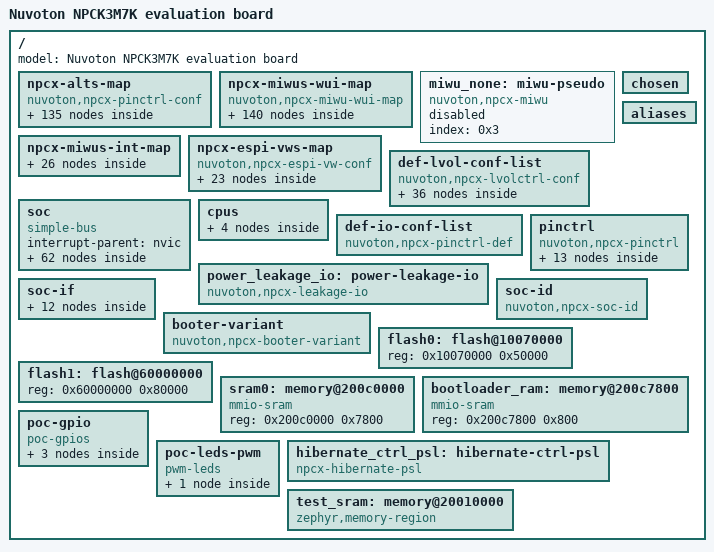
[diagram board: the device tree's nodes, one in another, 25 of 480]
/dts-v1/;

/ {
	#address-cells = < 0x1 >;
	#size-cells = < 0x1 >;
	model = "Nuvoton NPCK3M7K evaluation board";
	npcx-alts-map {
		compatible = "nuvoton,npcx-pinctrl-conf";
		alt0_sp1i_sl: alt00 {
			alts = < &scfg 0x0 0x0 0x0 >;
		};
		alt0_sp1o_sl: alt01 {
			alts = < &scfg 0x0 0x1 0x0 >;
		};
		alt0_ckout_sl: alt02 {
			alts = < &scfg 0x0 0x2 0x0 >;
			phandle = < 0x108 >;
		};
		alt0_spip1_sl: alt03 {
			alts = < &scfg 0x0 0x3 0x0 >;
		};
		alt0_sp2ctl_sl: alt04 {
			alts = < &scfg 0x0 0x4 0x0 >;
		};
		alt0_pvt_spi_sl: alt05 {
			alts = < &scfg 0x0 0x5 0x0 >;
			phandle = < 0xc2 >;
		};
		alt0_shd_bkp_spi_sl: alt05-inv {
			alts = < &scfg 0x0 0x5 0x1 >;
			phandle = < 0xc3 >;
		};
		alt0_shdf_spi_quad: alt06 {
			alts = < &scfg 0x0 0x6 0x0 >;
			phandle = < 0xc4 >;
		};
		alt0_shd1_spi: alt07 {
			alts = < &scfg 0x0 0x7 0x0 >;
			phandle = < 0xc1 >;
		};
		alt1_ovt_sl: alt10 {
			alts = < &scfg 0x1 0x0 0x0 >;
		};
		alt1_urti_sl: alt11 {
			alts = < &scfg 0x1 0x1 0x0 >;
			phandle = < 0xe5 >;
		};
		alt1_urto1_sl: alt12 {
			alts = < &scfg 0x1 0x2 0x0 >;
			phandle = < 0xe6 >;
		};
		alt1_sp1ctl_sl: alt14 {
			alts = < &scfg 0x1 0x4 0x0 >;
		};
		alt1_dpwrok_sl_def: alt15 {
			alts = < &scfg 0x1 0x5 0x0 >;
			phandle = < 0xaf >;
		};
		alt1_vcc_pwrgd_sl_def: alt16 {
			alts = < &scfg 0x1 0x6 0x0 >;
			phandle = < 0xb0 >;
		};
		alt1_lpc_espi_def: alt17 {
			alts = < &scfg 0x1 0x7 0x0 >;
			phandle = < 0xb1 >;
		};
		alt2_lpcpd_sl: alt21 {
			alts = < &scfg 0x2 0x1 0x0 >;
		};
		alt2_clkrun_sl: alt22 {
			alts = < &scfg 0x2 0x2 0x0 >;
		};
		alt2_smi_sl: alt23 {
			alts = < &scfg 0x2 0x3 0x0 >;
		};
		alt2_serirq_sl: alt24 {
			alts = < &scfg 0x2 0x4 0x0 >;
		};
		alt2_ecsci_sl_def: alt25 {
			alts = < &scfg 0x2 0x5 0x0 >;
			phandle = < 0xb2 >;
		};
		alt2_smb1a_sl: alt26 {
			alts = < &scfg 0x2 0x6 0x0 >;
			phandle = < 0xc7 >;
		};
		alt2_smb1b_sl: alt27 {
			alts = < &scfg 0x2 0x7 0x0 >;
			phandle = < 0xc8 >;
		};
		alt3_ta1_1_sl: alt30 {
			alts = < &scfg 0x3 0x0 0x0 >;
			phandle = < 0xe9 >;
		};
		alt3_ta2_1_sl: alt31 {
			alts = < &scfg 0x3 0x1 0x0 >;
			phandle = < 0xed >;
		};
		alt3_tb1_1_sl: alt32 {
			alts = < &scfg 0x3 0x2 0x0 >;
			phandle = < 0xeb >;
		};
		alt3_tb2_1_sl: alt33 {
			alts = < &scfg 0x3 0x3 0x0 >;
			phandle = < 0xef >;
		};
		alt3_ta3_1_sl: alt34 {
			alts = < &scfg 0x3 0x4 0x0 >;
			phandle = < 0xf1 >;
		};
		alt3_tb3_1_sl: alt35 {
			alts = < &scfg 0x3 0x5 0x0 >;
			phandle = < 0xf3 >;
		};
		alt3_tb1_2_sl: alt36 {
			alts = < &scfg 0x3 0x6 0x0 >;
			phandle = < 0xec >;
		};
		alt3_ta1_2_sl: alt37 {
			alts = < &scfg 0x3 0x7 0x0 >;
			phandle = < 0xea >;
		};
		alt4_shd2_spi: alt40 {
			alts = < &scfg 0x4 0x0 0x0 >;
			phandle = < 0xc6 >;
		};
		alt4_noshd2_spi: alt40-inv {
			alts = < &scfg 0x4 0x0 0x1 >;
			phandle = < 0xc5 >;
		};
		alt4_ckout2_sl: alt41 {
			alts = < &scfg 0x4 0x1 0x0 >;
		};
		alt4_clk24m_in2_sl: alt42 {
			alts = < &scfg 0x4 0x2 0x0 >;
		};
		alt4_clk24m_in1_sl: alt43 {
			alts = < &scfg 0x4 0x3 0x0 >;
		};
		alt4_ps2_3_sl: alt44 {
			alts = < &scfg 0x4 0x4 0x0 >;
			phandle = < 0xe8 >;
		};
		alt4_ps2_2_sl: alt46 {
			alts = < &scfg 0x4 0x6 0x0 >;
			phandle = < 0xe7 >;
		};
		alt5_a_pwm_sl: alt50 {
			alts = < &scfg 0x5 0x0 0x0 >;
			phandle = < 0xd1 >;
		};
		alt5_b_pwm_sl: alt51 {
			alts = < &scfg 0x5 0x1 0x0 >;
			phandle = < 0xd2 >;
		};
		alt5_c_pwm_sl: alt52 {
			alts = < &scfg 0x5 0x2 0x0 >;
			phandle = < 0xd3 >;
		};
		alt5_d_pwm_sl: alt53 {
			alts = < &scfg 0x5 0x3 0x0 >;
			phandle = < 0xd4 >;
		};
		alt5_f_pwm_sl: alt55 {
			alts = < &scfg 0x5 0x5 0x0 >;
			phandle = < 0xd5 >;
		};
		alt6_adc0_sl: alt60 {
			alts = < &scfg 0x6 0x0 0x0 >;
			phandle = < 0xd9 >;
		};
		alt6_adc1_sl: alt61 {
			alts = < &scfg 0x6 0x1 0x0 >;
			phandle = < 0xda >;
		};
		alt6_adc2_sl: alt62 {
			alts = < &scfg 0x6 0x2 0x0 >;
			phandle = < 0xdb >;
		};
		alt6_adc3_sl: alt63 {
			alts = < &scfg 0x6 0x3 0x0 >;
			phandle = < 0xdc >;
		};
		alt6_adc4_sl: alt64 {
			alts = < &scfg 0x6 0x4 0x0 >;
			phandle = < 0xdd >;
		};
		alt6_adc5_sl: alt65 {
			alts = < &scfg 0x6 0x5 0x0 >;
			phandle = < 0xde >;
		};
		alt6_adc6_sl: alt66 {
			alts = < &scfg 0x6 0x6 0x0 >;
			phandle = < 0xdf >;
		};
		alt6_adc7_sl: alt67 {
			alts = < &scfg 0x6 0x7 0x0 >;
			phandle = < 0xe0 >;
		};
		alt7_kso12_sl_def: alt72 {
			alts = < &scfg 0x7 0x2 0x0 >;
			phandle = < 0xb3 >;
		};
		alt7_kso13_sl_def: alt73 {
			alts = < &scfg 0x7 0x3 0x0 >;
			phandle = < 0xb4 >;
		};
		alt7_kso14_sl_def: alt74 {
			alts = < &scfg 0x7 0x4 0x0 >;
			phandle = < 0xb5 >;
		};
		alt7_kso15_sl_def: alt75 {
			alts = < &scfg 0x7 0x5 0x0 >;
			phandle = < 0xb6 >;
		};
		alt7_kso16_sl: alt76 {
			alts = < &scfg 0x7 0x6 0x0 >;
			phandle = < 0xf9 >;
		};
		alt7_kso17_sl: alt77 {
			alts = < &scfg 0x7 0x7 0x0 >;
			phandle = < 0xfa >;
		};
		alt8_ga20_sl: alt81 {
			alts = < &scfg 0x8 0x1 0x0 >;
		};
		alt8_kbrst_sl_def: alt82 {
			alts = < &scfg 0x8 0x2 0x0 >;
			phandle = < 0xb7 >;
		};
		alt8_k_pwm_sl: alt85 {
			alts = < &scfg 0x8 0x5 0x0 >;
			phandle = < 0xd8 >;
		};
		alt8_j_pwm_sl: alt86 {
			alts = < &scfg 0x8 0x6 0x0 >;
			phandle = < 0xd7 >;
		};
		alt8_i_pwm_sl: alt87 {
			alts = < &scfg 0x8 0x7 0x0 >;
			phandle = < 0xd6 >;
		};
		alt9_no_ksi0_ksi1_ksi2_ksi3_sl: alt90-inv {
			alts = < &scfg 0x9 0x0 0x1 >;
			phandle = < 0xb8 >;
		};
		alt9_no_ksi4_ksi5_sl: alt92-inv {
			alts = < &scfg 0x9 0x2 0x1 >;
			phandle = < 0xb9 >;
		};
		alt9_no_ksi6_ksi7_sl: alt93-inv {
			alts = < &scfg 0x9 0x3 0x1 >;
			phandle = < 0xba >;
		};
		alt9_no_kso0_kso1_kso2_kso3_sl: alt94-inv {
			alts = < &scfg 0x9 0x4 0x1 >;
			phandle = < 0xbb >;
		};
		alt9_no_kso4_kso5_kso6_kso7_sl: alt95-inv {
			alts = < &scfg 0x9 0x5 0x1 >;
			phandle = < 0xbc >;
		};
		alt9_no_kso8_kso9_sl: alt96-inv {
			alts = < &scfg 0x9 0x6 0x1 >;
			phandle = < 0xbd >;
		};
		alt9_no_kso10_kso11_sl: alt97-inv {
			alts = < &scfg 0x9 0x7 0x1 >;
			phandle = < 0xbe >;
		};
		alta_shi_sl: alta0 {
			alts = < &scfg 0xa 0x0 0x0 >;
		};
		alta_smb6a_sl: alta1 {
			alts = < &scfg 0xa 0x1 0x0 >;
			phandle = < 0xd0 >;
		};
		alta_smb5a_sl: alta2 {
			alts = < &scfg 0xa 0x2 0x0 >;
			phandle = < 0xcf >;
		};
		alta_13c1a_sl: alta4 {
			alts = < &scfg 0xa 0x4 0x0 >;
		};
		alta_13c1b_sl: alta5 {
			alts = < &scfg 0xa 0x5 0x0 >;
		};
		alta_smb3a_sl: alta6 {
			alts = < &scfg 0xa 0x6 0x0 >;
			phandle = < 0xcb >;
		};
		alta_smb4a_sl: alta7 {
			alts = < &scfg 0xa 0x7 0x0 >;
			phandle = < 0xcd >;
		};
		altb_sp2i_sl: altb0 {
			alts = < &scfg 0xb 0x0 0x0 >;
		};
		altb_sp2o_sl: altb1 {
			alts = < &scfg 0xb 0x1 0x0 >;
		};
		altb_ri1_sl: altb2 {
			alts = < &scfg 0xb 0x2 0x0 >;
		};
		altb_cts1_sl: altb3 {
			alts = < &scfg 0xb 0x3 0x0 >;
		};
		altb_rts1_sl: altb4 {
			alts = < &scfg 0xb 0x4 0x0 >;
		};
		altb_ri2_sl: altb5 {
			alts = < &scfg 0xb 0x5 0x0 >;
		};
		altb_cts2_sl: altb6 {
			alts = < &scfg 0xb 0x6 0x0 >;
		};
		altb_rts2_sl: altb7 {
			alts = < &scfg 0xb 0x7 0x0 >;
		};
		altc_smb4b_sl: altc4 {
			alts = < &scfg 0xc 0x4 0x0 >;
			phandle = < 0xce >;
		};
		altc_smb3b_sl: altc5 {
			alts = < &scfg 0xc 0x5 0x0 >;
			phandle = < 0xcc >;
		};
		altc_smb2b_sl: altc6 {
			alts = < &scfg 0xc 0x6 0x0 >;
			phandle = < 0xca >;
		};
		altc_smb2a_sl: altc7 {
			alts = < &scfg 0xc 0x7 0x0 >;
			phandle = < 0xc9 >;
		};
		altd_gpstby0_out_in_sby: altd0 {
			alts = < &scfg 0xd 0x0 0x0 >;
		};
		altd_gpstby1_out_in_sby: altd1 {
			alts = < &scfg 0xd 0x1 0x0 >;
		};
		altd_psl_in0_en_out_def: altd2 {
			alts = < &scfg 0xd 0x2 0x0 >;
		};
		altd_psl_in1_en_out_def: altd3 {
			alts = < &scfg 0xd 0x3 0x0 >;
		};
		altd_psl_in2_en_out_def: altd4 {
			alts = < &scfg 0xd 0x4 0x0 >;
		};
		altd_psl_in3_en_out_def: altd5 {
			alts = < &scfg 0xd 0x5 0x0 >;
		};
		altd_psl_in4_en_out_def: altd6 {
			alts = < &scfg 0xd 0x6 0x0 >;
		};
		altd_psl_in5_en_out_def: altd7 {
			alts = < &scfg 0xd 0x7 0x0 >;
		};
		alte_spip2_sl: alte5 {
			alts = < &scfg 0xe 0x5 0x0 >;
		};
		altf_psl_in0_en_def: altf1 {
			alts = < &scfg 0xf 0x1 0x0 >;
			phandle = < 0xbf >;
		};
		altf_psl_in1_en_def: altf2 {
			alts = < &scfg 0xf 0x2 0x0 >;
			phandle = < 0xc0 >;
		};
		altf_psl_in2_en: altf3 {
			alts = < &scfg 0xf 0x3 0x0 >;
			phandle = < 0xfd >;
		};
		altf_psl_in3_en: altf4 {
			alts = < &scfg 0xf 0x4 0x0 >;
			phandle = < 0xff >;
		};
		altf_psl_in4_en: altf5 {
			alts = < &scfg 0xf 0x5 0x0 >;
			phandle = < 0x101 >;
		};
		altf_psl_in5_en: altf6 {
			alts = < &scfg 0xf 0x6 0x0 >;
			phandle = < 0x103 >;
		};
		altf_psl_out_en_def: altf7 {
			alts = < &scfg 0xf 0x7 0x0 >;
			phandle = < 0x104 >;
		};
		alt10_tb5_sl: alt100 {
			alts = < &scfg 0x10 0x0 0x0 >;
			phandle = < 0xf8 >;
		};
		alt10_ta5_sl: alt101 {
			alts = < &scfg 0x10 0x1 0x0 >;
			phandle = < 0xf7 >;
		};
		alt10_tb4_sl: alt102 {
			alts = < &scfg 0x10 0x2 0x0 >;
			phandle = < 0xf6 >;
		};
		alt10_ta4_sl: alt103 {
			alts = < &scfg 0x10 0x3 0x0 >;
			phandle = < 0xf5 >;
		};
		alt10_tb3_2_sl: alt104 {
			alts = < &scfg 0x10 0x4 0x0 >;
			phandle = < 0xf4 >;
		};
		alt10_ta3_2_sl: alt105 {
			alts = < &scfg 0x10 0x5 0x0 >;
			phandle = < 0xf2 >;
		};
		alt10_tb2_2_sl: alt106 {
			alts = < &scfg 0x10 0x6 0x0 >;
			phandle = < 0xf0 >;
		};
		alt10_ta2_2_sl: alt107 {
			alts = < &scfg 0x10 0x7 0x0 >;
			phandle = < 0xee >;
		};
		alt11_adc8_sl: alt110 {
			alts = < &scfg 0x11 0x0 0x0 >;
			phandle = < 0xe1 >;
		};
		alt11_adc9_sl: alt111 {
			alts = < &scfg 0x11 0x1 0x0 >;
			phandle = < 0xe2 >;
		};
		alt11_adc10_sl: alt112 {
			alts = < &scfg 0x11 0x2 0x0 >;
			phandle = < 0xe3 >;
		};
		alt11_adc11_sl: alt113 {
			alts = < &scfg 0x11 0x3 0x0 >;
			phandle = < 0xe4 >;
		};
		smb1a_pu_sl: alt120 {
			alts = < &scfg 0x12 0x0 0x0 >;
		};
		smb1b_pu_sl: alt121 {
			alts = < &scfg 0x12 0x1 0x0 >;
		};
		smb2a_pu_sl: alt122 {
			alts = < &scfg 0x12 0x2 0x0 >;
		};
		smb2b_pu_sl: alt123 {
			alts = < &scfg 0x12 0x3 0x0 >;
		};
		smb3a_pu_sl: alt124 {
			alts = < &scfg 0x12 0x4 0x0 >;
		};
		smb3b_pu_sl: alt125 {
			alts = < &scfg 0x12 0x5 0x0 >;
		};
		smb4a_pu_sl: alt126 {
			alts = < &scfg 0x12 0x6 0x0 >;
		};
		smb4b_pu_sl: alt127 {
			alts = < &scfg 0x12 0x7 0x0 >;
		};
		altcx_psl_in0_ahi: alt131 {
			alts = < &scfg 0x13 0x1 0x0 >;
			phandle = < 0xfb >;
		};
		altcx_psl_in1_ahi: alt132 {
			alts = < &scfg 0x13 0x2 0x0 >;
			phandle = < 0xfc >;
		};
		altcx_psl_in2_ahi: alt133 {
			alts = < &scfg 0x13 0x3 0x0 >;
			phandle = < 0xfe >;
		};
		altcx_psl_in3_ahi: alt134 {
			alts = < &scfg 0x13 0x4 0x0 >;
			phandle = < 0x100 >;
		};
		altcx_psl_in4_ahi: alt135 {
			alts = < &scfg 0x13 0x5 0x0 >;
			phandle = < 0x102 >;
		};
		altcx_psl_in5_ahi: alt136 {
			alts = < &scfg 0x13 0x6 0x0 >;
		};
		altcx_gpio_out_pullen: alt137 {
			alts = < &scfg 0x13 0x7 0x0 >;
		};
		altdx_psl_out_gpo: alt140 {
			alts = < &scfg 0x14 0x0 0x0 >;
			phandle = < 0x107 >;
		};
		altdx_psl_fw_ctl_high: alt141 {
			alts = < &scfg 0x14 0x1 0x0 >;
			phandle = < 0x105 >;
		};
		altdx_psl_fw_ctl_low: alt141-inv {
			alts = < &scfg 0x14 0x1 0x1 >;
			phandle = < 0x106 >;
		};
		altdx_gpstby_rst_bit: alt147 {
			alts = < &scfg 0x14 0x7 0x0 >;
		};
	};
	npcx-miwus-wui-map {
		compatible = "nuvoton,npcx-miwu-wui-map";
		wui_io01: wui0-1-1 {
			miwus = < &miwu0 0x0 0x1 >;
			phandle = < 0x14 >;
		};
		wui_io02: wui0-1-2 {
			miwus = < &miwu0 0x0 0x2 >;
			phandle = < 0x15 >;
		};
		wui_io03: wui0-1-3 {
			miwus = < &miwu0 0x0 0x3 >;
			phandle = < 0x16 >;
		};
		wui_io04: wui0-1-4 {
			miwus = < &miwu0 0x0 0x4 >;
			phandle = < 0x17 >;
		};
		wui_io05: wui0-1-5 {
			miwus = < &miwu0 0x0 0x5 >;
			phandle = < 0x18 >;
		};
		wui_io07: wui0-1-7 {
			miwus = < &miwu0 0x0 0x7 >;
			phandle = < 0x19 >;
		};
		wui_io10: wui0-2-0 {
			miwus = < &miwu0 0x1 0x0 >;
			phandle = < 0x1d >;
		};
		wui_io11: wui0-2-1 {
			miwus = < &miwu0 0x1 0x1 >;
			phandle = < 0x1e >;
		};
		wui_io13: wui0-2-3 {
			miwus = < &miwu0 0x1 0x3 >;
			phandle = < 0x1f >;
		};
		wui_io14: wui0-2-4 {
			miwus = < &miwu0 0x1 0x4 >;
			phandle = < 0x20 >;
		};
		wui_io15: wui0-2-5 {
			miwus = < &miwu0 0x1 0x5 >;
			phandle = < 0x21 >;
		};
		wui_io17: wui0-2-7 {
			miwus = < &miwu0 0x1 0x7 >;
			phandle = < 0x22 >;
		};
		wui_io20: wui0-3-0 {
			miwus = < &miwu0 0x2 0x0 >;
			phandle = < 0x26 >;
		};
		wui_io21: wui0-3-1 {
			miwus = < &miwu0 0x2 0x1 >;
			phandle = < 0x27 >;
		};
		wui_io22: wui0-3-2 {
			miwus = < &miwu0 0x2 0x2 >;
			phandle = < 0x28 >;
		};
		wui_io23: wui0-3-3 {
			miwus = < &miwu0 0x2 0x3 >;
			phandle = < 0x29 >;
		};
		wui_io25: wui0-3-5 {
			miwus = < &miwu0 0x2 0x5 >;
			phandle = < 0x2a >;
		};
		wui_io26: wui0-3-6 {
			miwus = < &miwu0 0x2 0x6 >;
			phandle = < 0x2b >;
		};
		wui_io27: wui0-3-7 {
			miwus = < &miwu0 0x2 0x7 >;
			phandle = < 0x2c >;
		};
		wui_io30: wui0-4-0 {
			miwus = < &miwu0 0x3 0x0 >;
			phandle = < 0x32 >;
		};
		wui_io31: wui0-4-1 {
			miwus = < &miwu0 0x3 0x1 >;
			phandle = < 0x33 >;
		};
		wui_io32: wui0-4-2 {
			miwus = < &miwu0 0x3 0x2 >;
			phandle = < 0x34 >;
		};
		wui_io33: wui0-4-3 {
			miwus = < &miwu0 0x3 0x3 >;
			phandle = < 0x35 >;
		};
		wui_io34: wui0-4-4 {
			miwus = < &miwu0 0x3 0x4 >;
			phandle = < 0x36 >;
		};
		wui_io36: wui0-4-6 {
			miwus = < &miwu0 0x3 0x6 >;
			phandle = < 0x37 >;
		};
		wui_io40: wui0-5-0 {
			miwus = < &miwu0 0x4 0x0 >;
			phandle = < 0x39 >;
		};
		wui_io44: wui0-5-4 {
			miwus = < &miwu0 0x4 0x4 >;
			phandle = < 0x3a >;
		};
		wui_io45: wui0-5-5 {
			miwus = < &miwu0 0x4 0x5 >;
			phandle = < 0x3b >;
		};
		wui_io46: wui0-5-6 {
			miwus = < &miwu0 0x4 0x6 >;
			phandle = < 0x3c >;
		};
		wui_io47: wui0-5-7 {
			miwus = < &miwu0 0x4 0x7 >;
			phandle = < 0x3d >;
		};
		wui_io50: wui0-6-0 {
			miwus = < &miwu0 0x5 0x0 >;
			phandle = < 0x43 >;
		};
		wui_io51: wui0-6-1 {
			miwus = < &miwu0 0x5 0x1 >;
			phandle = < 0x44 >;
		};
		wui_io52: wui0-6-2 {
			miwus = < &miwu0 0x5 0x2 >;
			phandle = < 0x45 >;
		};
		wui_io53: wui0-6-3 {
			miwus = < &miwu0 0x5 0x3 >;
			phandle = < 0x46 >;
		};
		wui_io54: wui0-6-4 {
			miwus = < &miwu0 0x5 0x4 >;
			phandle = < 0x47 >;
		};
		wui_io55: wui0-6-5 {
			miwus = < &miwu0 0x5 0x5 >;
			phandle = < 0x48 >;
		};
		wui_io56: wui0-6-6 {
			miwus = < &miwu0 0x5 0x6 >;
			phandle = < 0x49 >;
		};
		wui_io57: wui0-6-7 {
			miwus = < &miwu0 0x5 0x7 >;
			phandle = < 0x4a >;
		};
		wui_io60: wui0-7-0 {
			miwus = < &miwu0 0x6 0x0 >;
			phandle = < 0x50 >;
		};
		wui_io61: wui0-7-1 {
			miwus = < &miwu0 0x6 0x1 >;
			phandle = < 0x51 >;
		};
		wui_io62: wui0-7-2 {
			miwus = < &miwu0 0x6 0x2 >;
			phandle = < 0x52 >;
		};
		wui_io63: wui0-7-3 {
			miwus = < &miwu0 0x6 0x3 >;
			phandle = < 0x53 >;
		};
		wui_io64: wui0-7-4 {
			miwus = < &miwu0 0x6 0x4 >;
			phandle = < 0x54 >;
		};
		wui_io65: wui0-7-5 {
			miwus = < &miwu0 0x6 0x5 >;
			phandle = < 0x55 >;
		};
		wui_io66: wui0-7-6 {
			miwus = < &miwu0 0x6 0x6 >;
			phandle = < 0x56 >;
		};
		wui_io67: wui0-7-7 {
			miwus = < &miwu0 0x6 0x7 >;
			phandle = < 0x57 >;
		};
		wui_io70: wui0-8-0 {
			miwus = < &miwu0 0x7 0x0 >;
			phandle = < 0x58 >;
		};
		wui_io72: wui0-8-2 {
			miwus = < &miwu0 0x7 0x2 >;
			phandle = < 0x59 >;
		};
		wui_io73: wui0-8-3 {
			miwus = < &miwu0 0x7 0x3 >;
			phandle = < 0x5a >;
		};
		wui_io74: wui0-8-4 {
			miwus = < &miwu0 0x7 0x4 >;
			phandle = < 0x5b >;
		};
		wui_io75: wui0-8-5 {
			miwus = < &miwu0 0x7 0x5 >;
			phandle = < 0x5c >;
		};
		wui_io76: wui0-8-6 {
			miwus = < &miwu0 0x7 0x6 >;
			phandle = < 0x5d >;
		};
		wui_io77: wui0-8-7 {
			miwus = < &miwu0 0x7 0x7 >;
			phandle = < 0x5e >;
		};
		wui_io81: wui1-1-1 {
			miwus = < &miwu1 0x0 0x1 >;
			phandle = < 0x61 >;
		};
		wui_io83: wui1-1-3 {
			miwus = < &miwu1 0x0 0x3 >;
			phandle = < 0x62 >;
		};
		wui_io85: wui1-1-5 {
			miwus = < &miwu1 0x0 0x5 >;
			phandle = < 0x63 >;
		};
		wui_io86: wui1-1-6 {
			miwus = < &miwu1 0x0 0x6 >;
			phandle = < 0x64 >;
		};
		wui_io87: wui1-1-7 {
			miwus = < &miwu1 0x0 0x7 >;
			phandle = < 0x65 >;
		};
		wui_cr_sin1: wui1-1-7-1 {
			miwus = < &miwu1 0x0 0x7 >;
			phandle = < 0xaa >;
		};
		wui_io90: wui1-2-0 {
			miwus = < &miwu1 0x1 0x0 >;
			phandle = < 0x68 >;
		};
		wui_io91: wui1-2-1 {
			miwus = < &miwu1 0x1 0x1 >;
			phandle = < 0x69 >;
		};
		wui_io92: wui1-2-2 {
			miwus = < &miwu1 0x1 0x2 >;
			phandle = < 0x6a >;
		};
		wui_io93: wui1-2-3 {
			miwus = < &miwu1 0x1 0x3 >;
			phandle = < 0x6b >;
		};
		wui_io94: wui1-2-4 {
			miwus = < &miwu1 0x1 0x4 >;
			phandle = < 0x6c >;
		};
		wui_ioa0: wui1-3-0 {
			miwus = < &miwu1 0x2 0x0 >;
			phandle = < 0x6e >;
		};
		wui_ioa1: wui1-3-1 {
			miwus = < &miwu1 0x2 0x1 >;
			phandle = < 0x6f >;
		};
		wui_ioa2: wui1-3-2 {
			miwus = < &miwu1 0x2 0x2 >;
			phandle = < 0x70 >;
		};
		wui_ioa3: wui1-3-3 {
			miwus = < &miwu1 0x2 0x3 >;
			phandle = < 0x71 >;
		};
		wui_ioa4: wui1-3-4 {
			miwus = < &miwu1 0x2 0x4 >;
			phandle = < 0x72 >;
		};
		wui_ioa5: wui1-3-5 {
			miwus = < &miwu1 0x2 0x5 >;
			phandle = < 0x73 >;
		};
		wui_ioa6: wui1-3-6 {
			miwus = < &miwu1 0x2 0x6 >;
			phandle = < 0x74 >;
		};
		wui_ioa7: wui1-3-7 {
			miwus = < &miwu1 0x2 0x7 >;
			phandle = < 0x75 >;
		};
		wui_iob0: wui1-4-0 {
			miwus = < &miwu1 0x3 0x0 >;
			phandle = < 0x76 >;
		};
		wui_shi_cs: wui1-4-3 {
			miwus = < &miwu1 0x3 0x3 >;
		};
		wui_cdbgpwrupreq: wui1-4-4 {
			miwus = < &miwu1 0x3 0x4 >;
		};
		wui_lpc_ev_wkup: wui1-4-5 {
			miwus = < &miwu1 0x3 0x5 >;
		};
		wui_host_acc: wui1-4-6 {
			miwus = < &miwu1 0x3 0x6 >;
			phandle = < 0xa4 >;
		};
		wui_espi_rst: wui1-4-7 {
			miwus = < &miwu1 0x3 0x7 >;
			phandle = < 0xa2 >;
		};
		wui_mswc: wui1-5-2 {
			miwus = < &miwu1 0x4 0x2 >;
		};
		wui_t0out: wui1-5-3 {
			miwus = < &miwu1 0x4 0x3 >;
			phandle = < 0xa1 >;
		};
		wui_iod0: wui1-6-0 {
			miwus = < &miwu1 0x5 0x0 >;
			phandle = < 0x79 >;
		};
		wui_iod3: wui1-6-3 {
			miwus = < &miwu1 0x5 0x3 >;
			phandle = < 0x7a >;
		};
		wui_iod4: wui1-6-4 {
			miwus = < &miwu1 0x5 0x4 >;
			phandle = < 0x7b >;
		};
		wui_iod5: wui1-6-5 {
			miwus = < &miwu1 0x5 0x5 >;
			phandle = < 0x7c >;
		};
		wui_iod6: wui1-6-6 {
			miwus = < &miwu1 0x5 0x6 >;
			phandle = < 0x7d >;
		};
		wui_iod7: wui1-6-7 {
			miwus = < &miwu1 0x5 0x7 >;
			phandle = < 0x7e >;
		};
		wui_ioe0: wui1-7-0 {
			miwus = < &miwu1 0x6 0x0 >;
			phandle = < 0x81 >;
		};
		wui_ioe1: wui1-7-1 {
			miwus = < &miwu1 0x6 0x1 >;
			phandle = < 0x82 >;
		};
		wui_ioe2: wui1-7-2 {
			miwus = < &miwu1 0x6 0x2 >;
			phandle = < 0x83 >;
		};
		wui_ioe3: wui1-7-3 {
			miwus = < &miwu1 0x6 0x3 >;
			phandle = < 0x84 >;
		};
		wui_ioe4: wui1-7-4 {
			miwus = < &miwu1 0x6 0x4 >;
			phandle = < 0x85 >;
		};
		wui_ioe5: wui1-7-5 {
			miwus = < &miwu1 0x6 0x5 >;
			phandle = < 0x86 >;
		};
		wui_ioe6: wui1-7-6 {
			miwus = < &miwu1 0x6 0x6 >;
			phandle = < 0x87 >;
		};
		wui_mtc: wui1-8-0 {
			miwus = < &miwu1 0x7 0x0 >;
		};
		wui_smb1: wui1-8-1 {
			miwus = < &miwu1 0x7 0x1 >;
		};
		wui_smb2: wui1-8-2 {
			miwus = < &miwu1 0x7 0x2 >;
		};
		wui_smb3: wui1-8-3 {
			miwus = < &miwu1 0x7 0x3 >;
		};
		wui_smb4: wui1-8-4 {
			miwus = < &miwu1 0x7 0x4 >;
		};
		wui_smb5: wui1-8-5 {
			miwus = < &miwu1 0x7 0x5 >;
		};
		wui_smb6: wui1-8-6 {
			miwus = < &miwu1 0x7 0x6 >;
		};
		wui_vw_slp_s3: wui2-1-0 {
			miwus = < &miwu2 0x0 0x0 >;
			phandle = < 0x6 >;
		};
		wui_vw_slp_s4: wui2-1-1 {
			miwus = < &miwu2 0x0 0x1 >;
			phandle = < 0x7 >;
		};
		wui_vw_slp_s5: wui2-1-2 {
			miwus = < &miwu2 0x0 0x2 >;
			phandle = < 0x8 >;
		};
		wui_vw_sus_stat: wui2-1-4 {
			miwus = < &miwu2 0x0 0x4 >;
			phandle = < 0x9 >;
		};
		wui_vw_plt_rst: wui2-1-5 {
			miwus = < &miwu2 0x0 0x5 >;
			phandle = < 0xa >;
		};
		wui_vw_oob_rst_warn: wui2-1-6 {
			miwus = < &miwu2 0x0 0x6 >;
			phandle = < 0xb >;
		};
		wui_vw_host_rst_warn: wui2-2-0 {
			miwus = < &miwu2 0x1 0x0 >;
			phandle = < 0xc >;
		};
		wui_vw_sus_warn: wui2-2-4 {
			miwus = < &miwu2 0x1 0x4 >;
			phandle = < 0xd >;
		};
		wui_vw_sus_pwrdn_ack: wui2-2-5 {
			miwus = < &miwu2 0x1 0x5 >;
			phandle = < 0xe >;
		};
		wui_vw_slp_a: wui2-2-7 {
			miwus = < &miwu2 0x1 0x7 >;
			phandle = < 0xf >;
		};
		wui_vw_slp_lan: wui2-3-0 {
			miwus = < &miwu2 0x2 0x0 >;
			phandle = < 0x10 >;
		};
		wui_vw_slp_wlan: wui2-3-1 {
			miwus = < &miwu2 0x2 0x1 >;
			phandle = < 0x11 >;
		};
		wui_vw_pch_to_ec_gen_0: wui2-3-4 {
			miwus = < &miwu2 0x2 0x4 >;
		};
		wui_vw_pch_to_ec_gen_1: wui2-3-5 {
			miwus = < &miwu2 0x2 0x5 >;
		};
		wui_vw_pch_to_ec_gen_2: wui2-3-6 {
			miwus = < &miwu2 0x2 0x6 >;
		};
		wui_vw_pch_to_ec_gen_3: wui2-3-7 {
			miwus = < &miwu2 0x2 0x7 >;
		};
		wui_vw_pch_to_ec_gen_4: wui2-4-0 {
			miwus = < &miwu2 0x3 0x0 >;
		};
		wui_vw_pch_to_ec_gen_5: wui2-4-1 {
			miwus = < &miwu2 0x3 0x1 >;
		};
		wui_vw_pch_to_ec_gen_6: wui2-4-2 {
			miwus = < &miwu2 0x3 0x2 >;
		};
		wui_vw_pch_to_ec_gen_7: wui2-4-3 {
			miwus = < &miwu2 0x3 0x3 >;
		};
		wui_vw_host_c10: wui2-4-4 {
			miwus = < &miwu2 0x3 0x4 >;
		};
		wui_iog5: wui2-5-5 {
			miwus = < &miwu2 0x4 0x5 >;
			phandle = < 0x8d >;
		};
		wui_iog6: wui2-5-6 {
			miwus = < &miwu2 0x4 0x6 >;
			phandle = < 0x8e >;
		};
		wui_iog7: wui2-5-7 {
			miwus = < &miwu2 0x4 0x7 >;
			phandle = < 0x8f >;
		};
		wui_ioh0: wui2-6-0 {
			miwus = < &miwu2 0x5 0x0 >;
			phandle = < 0x90 >;
		};
		wui_ioh1: wui2-6-1 {
			miwus = < &miwu2 0x5 0x1 >;
			phandle = < 0x91 >;
		};
		wui_ioh2: wui2-6-2 {
			miwus = < &miwu2 0x5 0x2 >;
			phandle = < 0x92 >;
		};
		wui_ioh4: wui2-6-4 {
			miwus = < &miwu2 0x5 0x4 >;
			phandle = < 0x93 >;
		};
		wui_io_stb00: wui2-7-0 {
			miwus = < &miwu2 0x6 0x0 >;
			phandle = < 0x94 >;
		};
		wui_io_stb01: wui2-7-1 {
			miwus = < &miwu2 0x6 0x1 >;
			phandle = < 0x95 >;
		};
		wui_io_stb02: wui2-7-2 {
			miwus = < &miwu2 0x6 0x2 >;
			phandle = < 0x96 >;
		};
		wui_io_stb03: wui2-7-3 {
			miwus = < &miwu2 0x6 0x3 >;
			phandle = < 0x97 >;
		};
		wui_io_stb04: wui2-7-4 {
			miwus = < &miwu2 0x6 0x4 >;
			phandle = < 0x98 >;
		};
		wui_io_stb11_psl_in0: wui2-8-1 {
			miwus = < &miwu2 0x7 0x1 >;
			phandle = < 0x99 >;
		};
		wui_io_stb12_psl_in1: wui2-8-2 {
			miwus = < &miwu2 0x7 0x2 >;
			phandle = < 0x9a >;
		};
		wui_io_stb13_psl_in2: wui2-8-3 {
			miwus = < &miwu2 0x7 0x3 >;
			phandle = < 0x9b >;
		};
		wui_io_stb14_psl_in3: wui2-8-4 {
			miwus = < &miwu2 0x7 0x4 >;
			phandle = < 0x9c >;
		};
		wui_io_stb15_psl_in4: wui2-8-5 {
			miwus = < &miwu2 0x7 0x5 >;
			phandle = < 0x9d >;
		};
		wui_io_stb16_psl_in5: wui2-8-6 {
			miwus = < &miwu2 0x7 0x6 >;
			phandle = < 0x9e >;
		};
		wui_none: wui-pseudo {
			miwus = < &miwu_none 0x7 0x7 >;
			phandle = < 0x13 >;
		};
	};
	miwu_none: miwu-pseudo {
		compatible = "nuvoton,npcx-miwu";
		index = < 0x3 >;
		#miwu-cells = < 0x2 >;
		status = "disabled";
		phandle = < 0x5 >;
	};
	npcx-miwus-int-map {
		map_miwu0_groups: map-miwu0-groups {
			compatible = "nuvoton,npcx-miwu-int-map";
			parent = < &miwu0 >;
			group_a0: group-a0-map {
				irq = < 0x28 >;
				irq-prio = < 0x2 >;
				group-mask = < 0x1 >;
			};
			group_b0: group-b0-map {
				irq = < 0x29 >;
				irq-prio = < 0x2 >;
				group-mask = < 0x2 >;
			};
			group_c0: group-c0-map {
				irq = < 0x2a >;
				irq-prio = < 0x2 >;
				group-mask = < 0x4 >;
			};
			group_d0: group-d0-map {
				irq = < 0x2b >;
				irq-prio = < 0x2 >;
				group-mask = < 0x8 >;
			};
			group_e0: group-e0-map {
				irq = < 0x2c >;
				irq-prio = < 0x2 >;
				group-mask = < 0x10 >;
			};
			group_f0: group-f0-map {
				irq = < 0x2d >;
				irq-prio = < 0x2 >;
				group-mask = < 0x20 >;
			};
			group_g0: group-g0-map {
				irq = < 0x2e >;
				irq-prio = < 0x2 >;
				group-mask = < 0x40 >;
			};
			group_h0: group-h0-map {
				irq = < 0x2f >;
				irq-prio = < 0x2 >;
				group-mask = < 0x80 >;
			};
		};
		map_miwu1_groups: map-miwu1-groups {
			compatible = "nuvoton,npcx-miwu-int-map";
			parent = < &miwu1 >;
			group_a1: group-a1-map {
				irq = < 0x30 >;
				irq-prio = < 0x2 >;
				group-mask = < 0x1 >;
			};
			group_b1: group-b1-map {
				irq = < 0x31 >;
				irq-prio = < 0x2 >;
				group-mask = < 0x2 >;
			};
			group_c1: group-c1-map {
				irq = < 0x32 >;
				irq-prio = < 0x2 >;
				group-mask = < 0x4 >;
			};
			group_d1: group-d1-map {
				irq = < 0x33 >;
				irq-prio = < 0x2 >;
				group-mask = < 0x8 >;
			};
			group_e1: group-e1-map {
				irq = < 0xc >;
				irq-prio = < 0x2 >;
				group-mask = < 0x10 >;
			};
			group_f1: group-f1-map {
				irq = < 0x35 >;
				irq-prio = < 0x2 >;
				group-mask = < 0x20 >;
			};
			group_g1: group-g1-map {
				irq = < 0x36 >;
				irq-prio = < 0x2 >;
				group-mask = < 0x40 >;
			};
		};
		map_miwu2_groups: map-miwu2-groups {
			compatible = "nuvoton,npcx-miwu-int-map";
			parent = < &miwu2 >;
			group_a2: group-a2-map {
				irq = < 0x3c >;
				irq-prio = < 0x2 >;
				group-mask = < 0x1 >;
			};
			group_b2: group-b2-map {
				irq = < 0x3d >;
				irq-prio = < 0x2 >;
				group-mask = < 0x2 >;
			};
			group_c2: group-c2-map {
				irq = < 0x3e >;
				irq-prio = < 0x2 >;
				group-mask = < 0x4 >;
			};
			group_d2: group-d2-map {
				irq = < 0x3f >;
				irq-prio = < 0x2 >;
				group-mask = < 0x8 >;
			};
			group_e2: group-e2-map {
				irq = < 0x38 >;
				irq-prio = < 0x2 >;
				group-mask = < 0x10 >;
			};
			group_f2: group-f2-map {
				irq = < 0x39 >;
				irq-prio = < 0x2 >;
				group-mask = < 0x20 >;
			};
			group_g2: group-g2-map {
				irq = < 0x3a >;
				irq-prio = < 0x2 >;
				group-mask = < 0x40 >;
			};
			group_h2: group-h2-map {
				irq = < 0x3b >;
				irq-prio = < 0x2 >;
				group-mask = < 0x80 >;
			};
		};
	};
	npcx-espi-vws-map {
		compatible = "nuvoton,npcx-espi-vw-conf";
		vw-slp-s3 {
			vw-reg = < 0x0 0x1 >;
			vw-wui = < &wui_vw_slp_s3 >;
		};
		vw-slp-s4 {
			vw-reg = < 0x0 0x2 >;
			vw-wui = < &wui_vw_slp_s4 >;
		};
		vw-slp-s5 {
			vw-reg = < 0x0 0x4 >;
			vw-wui = < &wui_vw_slp_s5 >;
		};
		vw-sus-stat {
			vw-reg = < 0x1 0x1 >;
			vw-wui = < &wui_vw_sus_stat >;
		};
		vw-plt-rst {
			vw-reg = < 0x1 0x2 >;
			vw-wui = < &wui_vw_plt_rst >;
		};
		vw-oob-rst-warn {
			vw-reg = < 0x1 0x4 >;
			vw-wui = < &wui_vw_oob_rst_warn >;
		};
		vw-host-rst-warn {
			vw-reg = < 0x2 0x1 >;
			vw-wui = < &wui_vw_host_rst_warn >;
		};
		vw-sus-warn {
			vw-reg = < 0x3 0x1 >;
			vw-wui = < &wui_vw_sus_warn >;
		};
		vw-sus-pwrdn-ack {
			vw-reg = < 0x3 0x2 >;
			vw-wui = < &wui_vw_sus_pwrdn_ack >;
		};
		vw-slp-a {
			vw-reg = < 0x3 0x8 >;
			vw-wui = < &wui_vw_slp_a >;
		};
		vw-slp-lan {
			vw-reg = < 0x4 0x1 >;
			vw-wui = < &wui_vw_slp_lan >;
		};
		vw-slp-wlan {
			vw-reg = < 0x4 0x2 >;
			vw-wui = < &wui_vw_slp_wlan >;
		};
		vw-oob-rst-ack {
			vw-reg = < 0x0 0x1 >;
		};
		vw-wake {
			vw-reg = < 0x0 0x4 >;
		};
		vw-pme {
			vw-reg = < 0x0 0x8 >;
		};
		vw-slv-boot-done {
			vw-reg = < 0x1 0x1 >;
		};
		vw-err-fatal {
			vw-reg = < 0x1 0x2 >;
		};
		vw-err-non-fatal {
			vw-reg = < 0x1 0x4 >;
		};
		vw-slv-boot-sts-with-done {
			vw-reg = < 0x1 0x9 >;
		};
		vw-sci {
			vw-reg = < 0x2 0x1 >;
		};
		vw-smi {
			vw-reg = < 0x2 0x2 >;
		};
		vw-host-rst-ack {
			vw-reg = < 0x2 0x8 >;
		};
		vw-sus-ack {
			vw-reg = < 0x3 0x1 >;
		};
	};
	def-lvol-conf-list {
		compatible = "nuvoton,npcx-lvolctrl-conf";
		lvol_io20: lvol00 {
			lvols = < &scfg 0x0 0x0 >;
			phandle = < 0x2d >;
		};
		lvol_io21: lvol01 {
			lvols = < &scfg 0x0 0x1 >;
			phandle = < 0x2e >;
		};
		lvol_io40: lvol02 {
			lvols = < &scfg 0x0 0x2 >;
			phandle = < 0x3e >;
		};
		lvol_io54: lvol03 {
			lvols = < &scfg 0x0 0x3 >;
			phandle = < 0x4f >;
		};
		lvol_io85: lvol05 {
			lvols = < &scfg 0x0 0x5 >;
			phandle = < 0x66 >;
		};
		lvol_io86: lvol06 {
			lvols = < &scfg 0x0 0x6 >;
			phandle = < 0x67 >;
		};
		lvol_io94: lvol07 {
			lvols = < &scfg 0x0 0x7 >;
			phandle = < 0x6d >;
		};
		lvol_iod5: lvol10 {
			lvols = < &scfg 0x1 0x0 >;
			phandle = < 0x7f >;
		};
		lvol_iod6: lvol11 {
			lvols = < &scfg 0x1 0x1 >;
			phandle = < 0x80 >;
		};
		lvol_io46: lvol12 {
			lvols = < &scfg 0x1 0x2 >;
			phandle = < 0x41 >;
		};
		lvol_io44: lvol13 {
			lvols = < &scfg 0x1 0x3 >;
			phandle = < 0x3f >;
		};
		lvol_io50: lvol14 {
			lvols = < &scfg 0x1 0x4 >;
			phandle = < 0x4b >;
		};
		lvol_io52: lvol15 {
			lvols = < &scfg 0x1 0x5 >;
			phandle = < 0x4d >;
		};
		lvol_ioe1: lvol16 {
			lvols = < &scfg 0x1 0x6 >;
			phandle = < 0x88 >;
		};
		lvol_ioe2: lvol17 {
			lvols = < &scfg 0x1 0x7 >;
			phandle = < 0x89 >;
		};
		lvol_io01: lvol20 {
			lvols = < &scfg 0x2 0x0 >;
			phandle = < 0x1b >;
		};
		lvol_io03: lvol21 {
			lvols = < &scfg 0x2 0x1 >;
			phandle = < 0x1c >;
		};
		lvol_io13: lvol22 {
			lvols = < &scfg 0x2 0x2 >;
			phandle = < 0x23 >;
		};
		lvol_io15: lvol23 {
			lvols = < &scfg 0x2 0x3 >;
			phandle = < 0x24 >;
		};
		lvol_io45: lvol24 {
			lvols = < &scfg 0x2 0x4 >;
			phandle = < 0x40 >;
		};
		lvol_io51: lvol25 {
			lvols = < &scfg 0x2 0x5 >;
			phandle = < 0x4c >;
		};
		lvol_ioe3: lvol26 {
			lvols = < &scfg 0x2 0x6 >;
			phandle = < 0x8a >;
		};
		lvol_ioe4: lvol27 {
			lvols = < &scfg 0x2 0x7 >;
			phandle = < 0x8b >;
		};
		lvol_io22: lvol30 {
			lvols = < &scfg 0x3 0x0 >;
			phandle = < 0x2f >;
		};
		lvol_io17: lvol31 {
			lvols = < &scfg 0x3 0x1 >;
			phandle = < 0x25 >;
		};
		lvol_io74: lvol32 {
			lvols = < &scfg 0x3 0x2 >;
			phandle = < 0x60 >;
		};
		lvol_io73: lvol33 {
			lvols = < &scfg 0x3 0x3 >;
			phandle = < 0x5f >;
		};
		lvol_io31: lvol34 {
			lvols = < &scfg 0x3 0x4 >;
			phandle = < 0x38 >;
		};
		lvol_io23: lvol35 {
			lvols = < &scfg 0x3 0x5 >;
			phandle = < 0x30 >;
		};
		lvol_io53: lvol36 {
			lvols = < &scfg 0x3 0x6 >;
			phandle = < 0x4e >;
		};
		lvol_io47: lvol37 {
			lvols = < &scfg 0x3 0x7 >;
			phandle = < 0x42 >;
		};
		lvol_io25: lvol40 {
			lvols = < &scfg 0x4 0x0 >;
			phandle = < 0x31 >;
		};
		lvol_ioe6: lvol41 {
			lvols = < &scfg 0x4 0x1 >;
			phandle = < 0x8c >;
		};
		lvol_ioc0: lvol42 {
			lvols = < &scfg 0x4 0x2 >;
			phandle = < 0x78 >;
		};
		lvol_iob7: lvol43 {
			lvols = < &scfg 0x4 0x3 >;
			phandle = < 0x77 >;
		};
		lvol_none: lvol-pseudo {
			lvols = < &scfg 0x1f 0x0 >;
			phandle = < 0x1a >;
		};
	};
	chosen {
		zephyr,flash = &flash0;
		zephyr,sram = &sram0;
		zephyr,console = &uart1;
		zephyr,shell-uart = &uart1;
	};
	aliases {
		gpio-out = &gpio_pulse_out;
		gpio-in = &gpio_pulse_in;
		gpio-obs = &gpio_observe_out;
	};
	soc {
		#address-cells = < 0x1 >;
		#size-cells = < 0x1 >;
		compatible = "simple-bus";
		interrupt-parent = < &nvic >;
		ranges;
		nvic: interrupt-controller@e000e100 {
			#address-cells = < 0x1 >;
			compatible = "arm,v7m-nvic";
			reg = < 0xe000e100 0xc00 >;
			interrupt-controller;
			#interrupt-cells = < 0x2 >;
			arm,num-irq-priority-bits = < 0x3 >;
			phandle = < 0x12 >;
		};
		systick: timer@e000e010 {
			compatible = "arm,armv7m-systick";
			reg = < 0xe000e010 0x10 >;
		};
		bbram: bb-ram@400af000 {
			compatible = "nuvoton,npcx-bbram";
			reg = < 0x400af000 0x80 0x400af100 0x1 >;
			reg-names = "memory", "status";
		};
		pcc: clock-controller@4000d000 {
			compatible = "nuvoton,npcx-pcc";
			#clock-cells = < 0x3 >;
			reg = < 0x4000d000 0x2000 0x400b5000 0x2000 >;
			reg-names = "pmc", "cdcg";
			clock-frequency = < 0x55d4a80 >;
			core-prescaler = < 0x6 >;
			apb1-prescaler = < 0x6 >;
			apb2-prescaler = < 0x6 >;
			apb3-prescaler = < 0x6 >;
			ram-pd-depth = < 0xf >;
			pwdwn-ctl-val = < 0xe7 0xfb 0xff 0x7f 0xb7 0xfa 0x7f >;
			phandle = < 0x9f >;
		};
		scfg: scfg@400c3000 {
			compatible = "nuvoton,npcx-scfg";
			reg = < 0x400c3000 0x70 0x400c3070 0x30 0x400a5000 0x2000 >;
			reg-names = "scfg", "dbg", "glue";
			#alt-cells = < 0x3 >;
			#lvol-cells = < 0x2 >;
			phandle = < 0x1 >;
		};
		mdc: mdc@4000c000 {
			compatible = "syscon";
			reg = < 0x4000c000 0xa >;
			reg-io-width = < 0x1 >;
		};
		mdc_header: mdc@4000c00a {
			compatible = "syscon";
			reg = < 0x4000c00a 0x4 >;
			reg-io-width = < 0x2 >;
		};
		miwu0: miwu@400bb000 {
			compatible = "nuvoton,npcx-miwu";
			reg = < 0x400bb000 0x2000 >;
			index = < 0x0 >;
			#miwu-cells = < 0x2 >;
			phandle = < 0x2 >;
		};
		miwu1: miwu@400bd000 {
			compatible = "nuvoton,npcx-miwu";
			reg = < 0x400bd000 0x2000 >;
			index = < 0x1 >;
			#miwu-cells = < 0x2 >;
			phandle = < 0x3 >;
		};
		miwu2: miwu@400bf000 {
			compatible = "nuvoton,npcx-miwu";
			reg = < 0x400bf000 0x2000 >;
			index = < 0x2 >;
			#miwu-cells = < 0x2 >;
			phandle = < 0x4 >;
		};
		gpio0: gpio@40081000 {
			compatible = "nuvoton,npcx-gpio";
			reg = < 0x40081000 0x2000 >;
			gpio-controller;
			index = < 0x0 >;
			#gpio-cells = < 0x2 >;
			wui-maps = < &wui_none &wui_io01 &wui_io02 &wui_io03 &wui_io04 &wui_io05 &wui_none &wui_io07 >;
			lvol-maps = < &lvol_none &lvol_io01 &lvol_none &lvol_io03 &lvol_none &lvol_none &lvol_none &lvol_none >;
		};
		gpio1: gpio@40083000 {
			compatible = "nuvoton,npcx-gpio";
			reg = < 0x40083000 0x2000 >;
			gpio-controller;
			index = < 0x1 >;
			#gpio-cells = < 0x2 >;
			wui-maps = < &wui_io10 &wui_io11 &wui_none &wui_io13 &wui_io14 &wui_io15 &wui_none &wui_io17 >;
			lvol-maps = < &lvol_none &lvol_none &lvol_none &lvol_io13 &lvol_none &lvol_io15 &lvol_none &lvol_io17 >;
		};
		gpio2: gpio@40085000 {
			compatible = "nuvoton,npcx-gpio";
			reg = < 0x40085000 0x2000 >;
			gpio-controller;
			index = < 0x2 >;
			#gpio-cells = < 0x2 >;
			wui-maps = < &wui_io20 &wui_io21 &wui_io22 &wui_io23 &wui_none &wui_io25 &wui_io26 &wui_io27 >;
			lvol-maps = < &lvol_io20 &lvol_io21 &lvol_io22 &lvol_io23 &lvol_none &lvol_io25 &lvol_none &lvol_none >;
		};
		gpio3: gpio@40087000 {
			compatible = "nuvoton,npcx-gpio";
			reg = < 0x40087000 0x2000 >;
			gpio-controller;
			index = < 0x3 >;
			#gpio-cells = < 0x2 >;
			wui-maps = < &wui_io30 &wui_io31 &wui_io32 &wui_io33 &wui_io34 &wui_none &wui_io36 &wui_none >;
			lvol-maps = < &lvol_none &lvol_io31 &lvol_none &lvol_none &lvol_none &lvol_none &lvol_none &lvol_none >;
		};
		gpio4: gpio@40089000 {
			compatible = "nuvoton,npcx-gpio";
			reg = < 0x40089000 0x2000 >;
			gpio-controller;
			index = < 0x4 >;
			#gpio-cells = < 0x2 >;
			wui-maps = < &wui_io40 &wui_none &wui_none &wui_none &wui_io44 &wui_io45 &wui_io46 &wui_io47 >;
			lvol-maps = < &lvol_io40 &lvol_none &lvol_none &lvol_none &lvol_io44 &lvol_io45 &lvol_io46 &lvol_io47 >;
		};
		gpio5: gpio@4008b000 {
			compatible = "nuvoton,npcx-gpio";
			reg = < 0x4008b000 0x2000 >;
			gpio-controller;
			index = < 0x5 >;
			#gpio-cells = < 0x2 >;
			wui-maps = < &wui_io50 &wui_io51 &wui_io52 &wui_io53 &wui_io54 &wui_io55 &wui_io56 &wui_io57 >;
			lvol-maps = < &lvol_io50 &lvol_io51 &lvol_io52 &lvol_io53 &lvol_io54 &lvol_none &lvol_none &lvol_none >;
		};
		gpio6: gpio@4008d000 {
			compatible = "nuvoton,npcx-gpio";
			reg = < 0x4008d000 0x2000 >;
			gpio-controller;
			index = < 0x6 >;
			#gpio-cells = < 0x2 >;
			wui-maps = < &wui_io60 &wui_io61 &wui_io62 &wui_io63 &wui_io64 &wui_io65 &wui_io66 &wui_io67 >;
			lvol-maps = < &lvol_none &lvol_none &lvol_none &lvol_none &lvol_none &lvol_none &lvol_none &lvol_none >;
		};
		gpio7: gpio@4008f000 {
			compatible = "nuvoton,npcx-gpio";
			reg = < 0x4008f000 0x2000 >;
			gpio-controller;
			index = < 0x7 >;
			#gpio-cells = < 0x2 >;
			wui-maps = < &wui_io70 &wui_none &wui_io72 &wui_io73 &wui_io74 &wui_io75 &wui_io76 &wui_io77 >;
			lvol-maps = < &lvol_none &lvol_none &lvol_none &lvol_io73 &lvol_io74 &lvol_none &lvol_none &lvol_none >;
		};
		gpio8: gpio@40091000 {
			compatible = "nuvoton,npcx-gpio";
			reg = < 0x40091000 0x2000 >;
			gpio-controller;
			index = < 0x8 >;
			#gpio-cells = < 0x2 >;
			wui-maps = < &wui_none &wui_io81 &wui_none &wui_io83 &wui_none &wui_io85 &wui_io86 &wui_io87 >;
			lvol-maps = < &lvol_none &lvol_none &lvol_none &lvol_none &lvol_none &lvol_io85 &lvol_io86 &lvol_none >;
		};
		gpio9: gpio@40093000 {
			compatible = "nuvoton,npcx-gpio";
			reg = < 0x40093000 0x2000 >;
			gpio-controller;
			index = < 0x9 >;
			#gpio-cells = < 0x2 >;
			wui-maps = < &wui_io90 &wui_io91 &wui_io92 &wui_io93 &wui_io94 &wui_none &wui_none &wui_none >;
			lvol-maps = < &lvol_none &lvol_none &lvol_none &lvol_none &lvol_io94 &lvol_none &lvol_none &lvol_none >;
		};
		gpioa: gpio@40095000 {
			compatible = "nuvoton,npcx-gpio";
			reg = < 0x40095000 0x2000 >;
			gpio-controller;
			index = < 0xa >;
			#gpio-cells = < 0x2 >;
			wui-maps = < &wui_ioa0 &wui_ioa1 &wui_ioa2 &wui_ioa3 &wui_ioa4 &wui_ioa5 &wui_ioa6 &wui_ioa7 >;
			lvol-maps = < &lvol_none &lvol_none &lvol_none &lvol_none &lvol_none &lvol_none &lvol_none &lvol_none >;
			phandle = < 0x10f >;
		};
		gpiob: gpio@40097000 {
			compatible = "nuvoton,npcx-gpio";
			reg = < 0x40097000 0x2000 >;
			gpio-controller;
			index = < 0xb >;
			#gpio-cells = < 0x2 >;
			wui-maps = < &wui_iob0 &wui_none &wui_none &wui_none &wui_none &wui_none &wui_none &wui_none >;
			lvol-maps = < &lvol_none &lvol_none &lvol_none &lvol_none &lvol_none &lvol_none &lvol_none &lvol_iob7 >;
		};
		gpioc: gpio@40099000 {
			compatible = "nuvoton,npcx-gpio";
			reg = < 0x40099000 0x2000 >;
			gpio-controller;
			index = < 0xc >;
			#gpio-cells = < 0x2 >;
			wui-maps = < &wui_none &wui_none &wui_none &wui_none &wui_none &wui_none &wui_none &wui_none >;
			lvol-maps = < &lvol_ioc0 &lvol_none &lvol_none &lvol_none &lvol_none &lvol_none &lvol_none &lvol_none >;
			phandle = < 0x110 >;
		};
		gpiod: gpio@4009b000 {
			compatible = "nuvoton,npcx-gpio";
			reg = < 0x4009b000 0x2000 >;
			gpio-controller;
			index = < 0xd >;
			#gpio-cells = < 0x2 >;
			wui-maps = < &wui_iod0 &wui_none &wui_none &wui_iod3 &wui_iod4 &wui_iod5 &wui_iod6 &wui_iod7 >;
			lvol-maps = < &lvol_none &lvol_none &lvol_none &lvol_none &lvol_none &lvol_iod5 &lvol_iod6 &lvol_none >;
		};
		gpioe: gpio@4009d000 {
			compatible = "nuvoton,npcx-gpio";
			reg = < 0x4009d000 0x2000 >;
			gpio-controller;
			index = < 0xe >;
			#gpio-cells = < 0x2 >;
			wui-maps = < &wui_ioe0 &wui_ioe1 &wui_ioe2 &wui_ioe3 &wui_ioe4 &wui_ioe5 &wui_ioe6 &wui_none >;
			lvol-maps = < &lvol_none &lvol_ioe1 &lvol_ioe2 &lvol_ioe3 &lvol_ioe4 &lvol_none &lvol_ioe6 &lvol_none >;
		};
		gpiof: gpio@4009f000 {
			compatible = "nuvoton,npcx-gpio";
			reg = < 0x4009f000 0x2000 >;
			gpio-controller;
			index = < 0xf >;
			#gpio-cells = < 0x2 >;
			wui-maps = < &wui_none &wui_none &wui_none &wui_none &wui_none &wui_none &wui_none &wui_none >;
			lvol-maps = < &lvol_none &lvol_none &lvol_none &lvol_none &lvol_none &lvol_none &lvol_none &lvol_none >;
		};
		gpiog: gpio@400a7000 {
			compatible = "nuvoton,npcx-gpio";
			reg = < 0x400a7000 0x2000 >;
			gpio-controller;
			index = < 0x10 >;
			#gpio-cells = < 0x2 >;
			wui-maps = < &wui_none &wui_none &wui_none &wui_none &wui_none &wui_iog5 &wui_iog6 &wui_iog7 >;
			lvol-maps = < &lvol_none &lvol_none &lvol_none &lvol_none &lvol_none &lvol_none &lvol_none &lvol_none >;
		};
		gpioh: gpio@400a9000 {
			compatible = "nuvoton,npcx-gpio";
			reg = < 0x400a9000 0x2000 >;
			gpio-controller;
			index = < 0x11 >;
			#gpio-cells = < 0x2 >;
			wui-maps = < &wui_ioh0 &wui_ioh1 &wui_ioh2 &wui_none &wui_ioh4 &wui_none &wui_none &wui_none >;
			lvol-maps = < &lvol_none &lvol_none &lvol_none &lvol_none &lvol_none &lvol_none &lvol_none &lvol_none >;
		};
		gpiostb0: gpio@400ab000 {
			compatible = "nuvoton,npcx-gpio";
			reg = < 0x400ab000 0x2000 >;
			gpio-controller;
			index = < 0x12 >;
			#gpio-cells = < 0x2 >;
			wui-maps = < &wui_io_stb00 &wui_io_stb01 &wui_io_stb02 &wui_io_stb03 &wui_io_stb04 &wui_none &wui_none &wui_none >;
			lvol-maps = < &lvol_none &lvol_none &lvol_none &lvol_none &lvol_none &lvol_none &lvol_none &lvol_none >;
		};
		gpiostb1: gpio@400ad000 {
			compatible = "nuvoton,npcx-gpio";
			reg = < 0x400ad000 0x2000 >;
			gpio-controller;
			index = < 0x13 >;
			#gpio-cells = < 0x2 >;
			wui-maps = < &wui_none &wui_io_stb11_psl_in0 &wui_io_stb12_psl_in1 &wui_io_stb13_psl_in2 &wui_io_stb14_psl_in3 &wui_io_stb15_psl_in4 &wui_io_stb16_psl_in5 &wui_none >;
			lvol-maps = < &lvol_none &lvol_none &lvol_none &lvol_none &lvol_none &lvol_none &lvol_none &lvol_none >;
		};
		pwma: pwm@40080000 {
			compatible = "nuvoton,npcx-pwm";
			reg = < 0x40080000 0x2000 >;
			pwm-channel = < 0x0 >;
			clocks = < &pcc 0x6 0x2 0x0 >;
			#pwm-cells = < 0x3 >;
			status = "disabled";
		};
		pwmb: pwm@40082000 {
			compatible = "nuvoton,npcx-pwm";
			reg = < 0x40082000 0x2000 >;
			pwm-channel = < 0x1 >;
			clocks = < &pcc 0x6 0x2 0x1 >;
			#pwm-cells = < 0x3 >;
			status = "okay";
			pinctrl-0 = < &pwmb_gp21 >;
			pinctrl-names = "default";
			phandle = < 0x111 >;
		};
		pwmc: pwm@40084000 {
			compatible = "nuvoton,npcx-pwm";
			reg = < 0x40084000 0x2000 >;
			pwm-channel = < 0x2 >;
			clocks = < &pcc 0x6 0x2 0x2 >;
			#pwm-cells = < 0x3 >;
			status = "disabled";
		};
		pwmd: pwm@40086000 {
			compatible = "nuvoton,npcx-pwm";
			reg = < 0x40086000 0x2000 >;
			pwm-channel = < 0x3 >;
			clocks = < &pcc 0x6 0x2 0x3 >;
			#pwm-cells = < 0x3 >;
			status = "disabled";
		};
		pwmf: pwm@4008a000 {
			compatible = "nuvoton,npcx-pwm";
			reg = < 0x4008a000 0x2000 >;
			pwm-channel = < 0x5 >;
			clocks = < &pcc 0x6 0x2 0x5 >;
			#pwm-cells = < 0x3 >;
			status = "disabled";
		};
		pwmi: pwm@40090000 {
			compatible = "nuvoton,npcx-pwm";
			reg = < 0x40090000 0x2000 >;
			pwm-channel = < 0x9 >;
			clocks = < &pcc 0x6 0x0 0x0 >;
			#pwm-cells = < 0x3 >;
			status = "disabled";
		};
		pwmj: pwm@40092000 {
			compatible = "nuvoton,npcx-pwm";
			reg = < 0x40092000 0x2000 >;
			pwm-channel = < 0xa >;
			clocks = < &pcc 0x6 0x0 0x1 >;
			#pwm-cells = < 0x3 >;
			status = "disabled";
		};
		pwmk: pwm@40094000 {
			compatible = "nuvoton,npcx-pwm";
			reg = < 0x40094000 0x2000 >;
			pwm-channel = < 0xb >;
			clocks = < &pcc 0x6 0x0 0x2 >;
			#pwm-cells = < 0x3 >;
			status = "disabled";
		};
		adc0: adc@400d1000 {
			compatible = "nuvoton,npcx-adc";
			#io-channel-cells = < 0x1 >;
			reg = < 0x400d1000 0x2000 >;
			interrupts = < 0x15 0x3 >;
			clocks = < &pcc 0x5 0x4 0x4 >;
			vref-mv = < 0xce4 >;
			status = "disabled";
			channel-count = < 0xc >;
			threshold-count = < 0x6 >;
		};
		twd0: watchdog@400d8000 {
			compatible = "nuvoton,npcx-watchdog";
			reg = < 0x400d8000 0x2000 >;
			t0-out = < &wui_t0out >;
		};
		espi0: espi@4000a000 {
			compatible = "nuvoton,npcx-espi";
			reg = < 0x4000a000 0x2000 >;
			interrupts = < 0xb 0x3 >;
			clocks = < &pcc 0x7 0x6 0x7 >;
			espi-rst-wui = < &wui_espi_rst >;
			rx-plsize = < 0x40 >;
			tx-plsize = < 0x40 >;
			#address-cells = < 0x1 >;
			#size-cells = < 0x0 >;
			#vw-cells = < 0x3 >;
			status = "okay";
			pinctrl-0 = < &espi_lpc_gp10_f7 >;
			pinctrl-names = "default";
		};
		host_sub: lpc@400c1000 {
			compatible = "nuvoton,npcx-host-sub";
			reg = < 0x400c1000 0x2000 0x40010000 0x2000 0x4000e000 0x2000 0x400c7000 0x2000 0x400c9000 0x2000 0x400cb000 0x2000 >;
			reg-names = "mswc", "shm", "c2h", "kbc", "pm_acpi", "pm_hcmd";
			interrupts = < 0x6 0x3 >, < 0x5 0x3 >, < 0x4 0x3 >, < 0x3 0x3 >, < 0xa 0x3 >;
			interrupt-names = "kbc_ibf", "kbc_obe", "pmch_ibf", "pmch_obe", "p80_fifo";
			host-acc-wui = < &wui_host_acc >;
			clocks = < &pcc 0x7 0x5 0x3 >, < &pcc 0x7 0x5 0x4 >, < &pcc 0x7 0x5 0x5 >, < &pcc 0x7 0x5 0x6 >, < &pcc 0x5 0x5 0x7 >;
		};
		i2c_ctrl1: i2c@40003000 {
			compatible = "nuvoton,npcx-i2c-ctrl";
			reg = < 0x40003000 0x1000 >;
			interrupts = < 0x23 0x3 >;
			clocks = < &pcc 0x7 0x3 0x0 >;
			status = "disabled";
			phandle = < 0x109 >;
		};
		i2c_ctrl2: i2c@40004000 {
			compatible = "nuvoton,npcx-i2c-ctrl";
			reg = < 0x40004000 0x1000 >;
			interrupts = < 0x24 0x3 >;
			clocks = < &pcc 0x7 0x3 0x1 >;
			status = "disabled";
			phandle = < 0x10a >;
		};
		i2c_ctrl3: i2c@40005000 {
			compatible = "nuvoton,npcx-i2c-ctrl";
			reg = < 0x40005000 0x1000 >;
			interrupts = < 0x25 0x3 >;
			clocks = < &pcc 0x7 0x3 0x2 >;
			status = "disabled";
			phandle = < 0x10b >;
		};
		i2c_ctrl4: i2c@40006000 {
			compatible = "nuvoton,npcx-i2c-ctrl";
			reg = < 0x40006000 0x1000 >;
			interrupts = < 0x26 0x3 >;
			clocks = < &pcc 0x7 0x3 0x3 >;
			status = "disabled";
			phandle = < 0x10c >;
		};
		i2c_ctrl5: i2c@40007000 {
			compatible = "nuvoton,npcx-i2c-ctrl";
			reg = < 0x40007000 0x1000 >;
			interrupts = < 0x27 0x3 >;
			clocks = < &pcc 0x7 0x3 0x4 >;
			status = "disabled";
			phandle = < 0x10d >;
		};
		i2c_ctrl6: i2c@40008000 {
			compatible = "nuvoton,npcx-i2c-ctrl";
			reg = < 0x40008000 0x1000 >;
			interrupts = < 0x14 0x3 >;
			clocks = < &pcc 0x7 0x3 0x5 >;
			status = "disabled";
			phandle = < 0x10e >;
		};
		tach1: tach@400e1000 {
			compatible = "nuvoton,npcx-tach";
			reg = < 0x400e1000 0x2000 >;
			clocks = < &pcc 0x1 0x1 0x5 >;
			status = "disabled";
		};
		tach2: tach@400e3000 {
			compatible = "nuvoton,npcx-tach";
			reg = < 0x400e3000 0x2000 >;
			clocks = < &pcc 0x1 0x1 0x6 >;
			status = "disabled";
		};
		tach3: tach@400e5000 {
			compatible = "nuvoton,npcx-tach";
			reg = < 0x400e5000 0x2000 >;
			clocks = < &pcc 0x1 0x1 0x7 >;
			status = "disabled";
		};
		tach4: tach@400e7000 {
			compatible = "nuvoton,npcx-tach";
			reg = < 0x400e7000 0x2000 >;
			clocks = < &pcc 0x1 0x0 0x5 >;
			status = "disabled";
		};
		tach5: tach@400e9000 {
			compatible = "nuvoton,npcx-tach";
			reg = < 0x400e9000 0x2000 >;
			clocks = < &pcc 0x1 0x0 0x6 >;
			status = "disabled";
		};
		ps2_ctrl0: ps2@400b1000 {
			compatible = "nuvoton,npcx-ps2-ctrl";
			reg = < 0x400b1000 0x1000 >;
			interrupts = < 0x8 0x4 >;
			clocks = < &pcc 0x0 0x1 0x3 >;
			ps2_channel2: io_ps2_channel2 {
				compatible = "nuvoton,npcx-ps2-channel";
				channel = < 0x1 >;
				status = "disabled";
			};
			ps2_channel3: io_ps2_channel3 {
				compatible = "nuvoton,npcx-ps2-channel";
				channel = < 0x2 >;
				status = "disabled";
			};
		};
		qspi_fiu0: quadspi@40020000 {
			compatible = "nuvoton,npcx-fiu-qspi";
			#address-cells = < 0x1 >;
			#size-cells = < 0x0 >;
			reg = < 0x40020000 0x1000 >;
			clocks = < &pcc 0x3 0x1 0x2 >;
			status = "okay";
			shd_flash: w25qshd@0 {
				compatible = "nuvoton,npcx-fiu-nor";
				size = < 0x800000 >;
				quad-enable-requirements = "S2B1v1";
				reg = < 0x0 >;
				status = "okay";
				qspi-flags = < 0x42 >;
				mapped-addr = < 0x70000000 >;
				pinctrl-0 = < &fiu_shd_io0_io1_clk_cs_gpc5_c4_c7_c6 &fiu_shd_quad_io2_io3_gp81_77 &fiu_shd_cs_gpc6_sl &shd_bkp_flash_tris_off &fiu_shd_bkp_flash_sl >;
				pinctrl-names = "default";
			};
		};
		peci0: peci@400d4000 {
			compatible = "nuvoton,npcx-peci";
			reg = < 0x400d4000 0x1000 >;
			#address-cells = < 0x1 >;
			#size-cells = < 0x0 >;
			interrupts = < 0x9 0x4 >;
			clocks = < &pcc 0xa 0x4 0x5 >;
			status = "disabled";
		};
		kbd: kscan@400a3000 {
			compatible = "nuvoton,npcx-kbd";
			reg = < 0x400a3000 0x2000 >;
			interrupts = < 0x32 0x4 >;
			clocks = < &pcc 0x5 0x1 0x0 >;
			wui-maps = < &wui_ioa0 &wui_ioa1 &wui_ioa2 &wui_ioa3 &wui_ioa4 &wui_ioa5 &wui_ioa6 &wui_ioa7 >;
			status = "disabled";
		};
		itims: timer@400b0000 {
			compatible = "nuvoton,npcx-itim-timer";
			reg = < 0x400b0000 0x2000 0x400bc000 0x2000 >;
			reg-names = "evt_itim", "sys_itim";
			clocks = < &pcc 0x1 0x4 0x0 &pcc 0x6 0x2 0x6 >;
			interrupts = < 0x1d 0x1 >, < 0x1e 0x1 >;
		};
		uart1: serial@400c4000 {
			compatible = "nuvoton,npcx-uart";
			reg = < 0x400c4000 0x2000 >;
			interrupts = < 0x17 0x3 >;
			clocks = < &pcc 0x6 0x1 0x4 >;
			uart-rx = < &wui_cr_sin1 >;
			status = "okay";
			current-speed = < 0x1c200 >;
			pinctrl-0 = < &uart1_sin_gp87 &uart1_sout_gp83 >;
			pinctrl-names = "default";
		};
	};
	cpus {
		#address-cells = < 0x1 >;
		#size-cells = < 0x0 >;
		cpu0: cpu@0 {
			device_type = "cpu";
			compatible = "arm,cortex-m4f";
			reg = < 0x0 >;
			cpu-power-states = < &suspend_to_idle0 &suspend_to_idle1 >;
		};
		power-states {
			suspend_to_idle0: suspend-to-idle0 {
				compatible = "zephyr,power-state";
				power-state-name = "suspend-to-idle";
				substate-id = < 0x0 >;
				min-residency-us = < 0x3e8 >;
				phandle = < 0xad >;
			};
			suspend_to_idle1: suspend-to-idle1 {
				compatible = "zephyr,power-state";
				power-state-name = "suspend-to-idle";
				substate-id = < 0x1 >;
				min-residency-us = < 0x31128 >;
				phandle = < 0xae >;
			};
		};
	};
	def-io-conf-list {
		compatible = "nuvoton,npcx-pinctrl-def";
		pinmux = < &alt1_dpwrok_sl_def &alt1_vcc_pwrgd_sl_def &alt1_lpc_espi_def &alt2_ecsci_sl_def &alt7_kso12_sl_def &alt7_kso13_sl_def &alt7_kso14_sl_def &alt7_kso15_sl_def &alt8_kbrst_sl_def &alt9_no_ksi0_ksi1_ksi2_ksi3_sl &alt9_no_ksi4_ksi5_sl &alt9_no_ksi6_ksi7_sl &alt9_no_kso0_kso1_kso2_kso3_sl &alt9_no_kso4_kso5_kso6_kso7_sl &alt9_no_kso8_kso9_sl &alt9_no_kso10_kso11_sl &altf_psl_in0_en_def &altf_psl_in1_en_def >;
	};
	pinctrl: pinctrl {
		compatible = "nuvoton,npcx-pinctrl";
		status = "okay";
		shd_bkp_flash_tris_off: devctl-fiu-ext-tris-off {
			dev-ctl = < 0x0 0x6 0x1 0x0 >;
			phandle = < 0xa8 >;
		};
		fiu_shd_io0_io1_clk_cs_gpc5_c4_c7_c6: periph-fiu-shd {
			pinmux = < &alt0_shd1_spi >;
			phandle = < 0xa5 >;
		};
		fiu_shd_bkp_flash_sl: periph-fiu-ext {
			pinmux = < &alt0_shd_bkp_spi_sl >;
			phandle = < 0xa9 >;
		};
		fiu_shd_quad_io2_io3_gp81_77: periph-fiu-shd-quad {
			pinmux = < &alt0_shdf_spi_quad >;
			phandle = < 0xa6 >;
		};
		fiu_shd_cs_gpc6_sl: periph-fiu-shd-cs1 {
			pinmux = < &alt4_noshd2_spi >;
			phandle = < 0xa7 >;
		};
		espi_lpc_gp10_f7: periph-lpc-espi {
			pinmux = < &alt1_lpc_espi_def >;
			phandle = < 0xa3 >;
		};
		pwmb_gp21: periph-pwm1 {
			pinmux = < &alt5_b_pwm_sl >;
			phandle = < 0xa0 >;
		};
		uart1_sin_gp87: periph-uart1-sin {
			pinmux = < &alt1_urti_sl >;
			phandle = < 0xab >;
		};
		uart1_sout_gp83: periph-uart1-sout {
			pinmux = < &alt1_urto1_sl >;
			phandle = < 0xac >;
		};
		psl_in1_gpstb12: periph-psl-in1 {
			pinmux = < &altf_psl_in1_en_def >;
			psl-offset = < 0x2 >;
			psl-polarity = < &altcx_psl_in1_ahi >;
			psl-in-mode = "edge";
			psl-in-pol = "high-rising";
			phandle = < 0x112 >;
		};
		psl_out_fw_high: periph-psl-out-inactive-high {
			pinmux = < &altdx_psl_fw_ctl_high >;
			phandle = < 0x113 >;
		};
		psl_out_fw_low: periph-psl-out-inactive-low {
			pinmux = < &altdx_psl_fw_ctl_low >;
			phandle = < 0x115 >;
		};
		psl_out_fw_ctl_en: periph-psl-out-fw-ctl {
			pinmux = < &altdx_psl_out_gpo >;
			phandle = < 0x114 >;
		};
	};
	power_leakage_io: power-leakage-io {
		compatible = "nuvoton,npcx-leakage-io";
		status = "okay";
	};
	soc-if {
		host_uart: io_host_uart {
			compatible = "nuvoton,npcx-host-uart";
			status = "disabled";
		};
		i2c1_a: io_i2c_ctrl1_porta {
			compatible = "nuvoton,npcx-i2c-port";
			#address-cells = < 0x1 >;
			#size-cells = < 0x0 >;
			port = < 0x0 >;
			controller = < &i2c_ctrl1 >;
			status = "disabled";
		};
		i2c1_b: io_i2c_ctrl1_portb {
			compatible = "nuvoton,npcx-i2c-port";
			#address-cells = < 0x1 >;
			#size-cells = < 0x0 >;
			port = < 0x1 >;
			controller = < &i2c_ctrl1 >;
			status = "disabled";
		};
		i2c2_a: io_i2c_ctrl2_porta {
			compatible = "nuvoton,npcx-i2c-port";
			#address-cells = < 0x1 >;
			#size-cells = < 0x0 >;
			port = < 0x10 >;
			controller = < &i2c_ctrl2 >;
			status = "disabled";
		};
		i2c2_b: io_i2c_ctrl2_portb {
			compatible = "nuvoton,npcx-i2c-port";
			#address-cells = < 0x1 >;
			#size-cells = < 0x0 >;
			port = < 0x11 >;
			controller = < &i2c_ctrl2 >;
			status = "disabled";
		};
		i2c3_a: io_i2c_ctrl3_porta {
			compatible = "nuvoton,npcx-i2c-port";
			#address-cells = < 0x1 >;
			#size-cells = < 0x0 >;
			port = < 0x20 >;
			controller = < &i2c_ctrl3 >;
			status = "disabled";
		};
		i2c3_b: io_i2c_ctrl3_portb {
			compatible = "nuvoton,npcx-i2c-port";
			#address-cells = < 0x1 >;
			#size-cells = < 0x0 >;
			port = < 0x21 >;
			controller = < &i2c_ctrl3 >;
			status = "disabled";
		};
		i2c4_a: io_i2c_ctrl4_porta {
			compatible = "nuvoton,npcx-i2c-port";
			#address-cells = < 0x1 >;
			#size-cells = < 0x0 >;
			port = < 0x30 >;
			controller = < &i2c_ctrl4 >;
			status = "disabled";
		};
		i2c4_b: io_i2c_ctrl4_portb {
			compatible = "nuvoton,npcx-i2c-port";
			#address-cells = < 0x1 >;
			#size-cells = < 0x0 >;
			port = < 0x31 >;
			controller = < &i2c_ctrl4 >;
			status = "disabled";
		};
		i2c5_a: io_i2c_ctrl5_porta {
			compatible = "nuvoton,npcx-i2c-port";
			#address-cells = < 0x1 >;
			#size-cells = < 0x0 >;
			port = < 0x40 >;
			controller = < &i2c_ctrl5 >;
			status = "disabled";
		};
		i2c6_a: io_i2c_ctrl6_porta {
			compatible = "nuvoton,npcx-i2c-port";
			#address-cells = < 0x1 >;
			#size-cells = < 0x0 >;
			controller = < &i2c_ctrl6 >;
			port = < 0x41 >;
			status = "disabled";
		};
		power_ctrl_psl: power-ctrl-psl {
			compatible = "nuvoton,npcx-power-psl";
			status = "disabled";
		};
	};
	soc-id {
		compatible = "nuvoton,npcx-soc-id";
		family-id = < 0x20 >;
		chip-id = < 0x9 >;
		revision-reg = < 0xfffc 0x4 >;
		device-id = < 0x22 >;
	};
	booter-variant {
		compatible = "nuvoton,npcx-booter-variant";
	};
	flash0: flash@10070000 {
		reg = < 0x10070000 0x50000 >;
	};
	flash1: flash@60000000 {
		reg = < 0x60000000 0x80000 >;
	};
	sram0: memory@200c0000 {
		compatible = "mmio-sram";
		reg = < 0x200c0000 0x7800 >;
	};
	bootloader_ram: memory@200c7800 {
		compatible = "mmio-sram";
		reg = < 0x200c7800 0x800 >;
	};
	poc-gpio {
		compatible = "poc-gpios";
		gpio_pulse_out: pulse_out {
			gpios = < &gpioa 0x5 0xa0000 >;
		};
		gpio_pulse_in: pulse_in {
			gpios = < &gpioa 0x0 0x10000 >;
		};
		gpio_observe_out: observe_out {
			gpios = < &gpioc 0x5 0xa0000 >;
		};
	};
	poc-leds-pwm {
		compatible = "pwm-leds";
		pwm_led0_green: pwm_led_0 {
			pwms = < &pwmb 0x0 0x1312d00 0x1 >;
			label = "User D7 green";
		};
	};
	hibernate_ctrl_psl: hibernate-ctrl-psl {
		compatible = "npcx-hibernate-psl";
		psl-driven-type = "fw-ctrl-driven";
		status = "okay";
		pinctrl-0 = < &psl_in1_gpstb12 >;
		pinctrl-1 = < &psl_out_fw_high &psl_out_fw_ctl_en &psl_out_fw_low >;
		pinctrl-names = "default", "hibernate";
	};
	test_sram: memory@20010000 {
		compatible = "zephyr,memory-region", "mmio-sram";
		reg = < 0x1315410 0x400 >;
		zephyr,memory-region = "LP_RAM";
	};
};
